# MKM14ZA5 register map
Vendor: Freescale Semiconductor, Inc.; Series: Kinetis_M; File version: 1.6
CPU: CM0PLUS r0p0, little endian, no MPU, no FPU, VTOR, 2 interrupt priority bits
Registers are 8-bit, read-write, reset 0x0 unless marked. A register's access mark holds for its fields unless they carry their own. Offsets are from the block's base; [hi:lo] are bit positions; {n}, {i} and the like mark numbered series.

## CMP0 — High-Speed Comparator (CMP), Voltage Reference (VREF) Digital-to-Analog Converter (DAC), and Analog Mux (ANMUX)
Base 0x40072000; register names take the prefix CMP0_
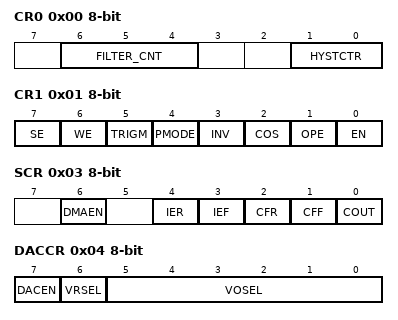
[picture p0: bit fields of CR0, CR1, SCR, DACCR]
0x00 CR0 — CMP Control Register 0
  [6:4] FILTER_CNT — Filter Sample Count
    0=Filter is disabled. If SE = 1, then COUT is a logic 0. This is not a legal state, and is not recommended. If SE = 0, COUT = COUTA.; 1=One sample must agree. The comparator output is simply sampled.; {v}={v} consecutive samples must agree (v=2..7)
  [1:0] HYSTCTR — Comparator hard block hysteresis control
    {v}=Level {v} (v=0..3)
0x01 CR1 — CMP Control Register 1
  [7] SE — Sample Enable
    0=Sampling mode is not selected; 1=Sampling mode is selected
  [6] WE — Windowing Enable
    0=Windowing mode is not selected; 1=Windowing mode is selected
  [5] TRIGM — Trigger Mode Enable
    0=Trigger mode is disabled; 1=Trigger mode is enabled
  [4] PMODE — Power Mode Select
    0=Low-Speed (LS) Comparison mode selected. In this mode, CMP has slower output propagation delay and lower current consumption.; 1=High-Speed (HS) Comparison mode selected. In this mode, CMP has faster output propagation delay and higher current consumption.
  [3] INV — Comparator INVERT
    0=Does not invert the comparator output; 1=Inverts the comparator output
  [2] COS — Comparator Output Select
    0=Set the filtered comparator output (CMPO) to equal COUT; 1=Set the unfiltered comparator output (CMPO) to equal COUTA
  [1] OPE — Comparator Output Pin Enable
    0=CMPO is not available on the associated CMPO output pin; 1=CMPO is available on the associated CMPO output pin
  [0] EN — Comparator Module Enable
    0=Analog Comparator is disabled; 1=Analog Comparator is enabled
0x02 FPR — CMP Filter Period Register
  [7:0] FILT_PER — Filter Sample Period
0x03 SCR — CMP Status and Control Register
  [6] DMAEN — DMA Enable Control
    0=DMA is disabled; 1=DMA is enabled
  [4] IER — Comparator Interrupt Enable Rising
    0=Interrupt is disabled; 1=Interrupt is enabled
  [3] IEF — Comparator Interrupt Enable Falling
    0=Interrupt is disabled; 1=Interrupt is enabled
  [2] CFR — Analog Comparator Flag Rising
    0=Rising-edge on COUT has not been detected; 1=Rising-edge on COUT has occurred
  [1] CFF — Analog Comparator Flag Falling
    0=Falling-edge on COUT has not been detected; 1=Falling-edge on COUT has occurred
  [0] COUT ro — Analog Comparator Output
0x04 DACCR — DAC Control Register
  [7] DACEN — DAC Enable
    0=DAC is disabled; 1=DAC is enabled
  [6] VRSEL — Supply Voltage Reference Source Select
    0=Vin1 is selected as resistor ladder network supply reference; 1=Vin2 is selected as resistor ladder network supply reference
  [5:0] VOSEL — DAC Output Voltage Select
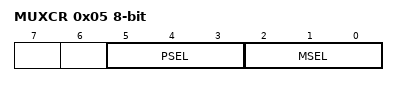
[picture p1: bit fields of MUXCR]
0x05 MUXCR — MUX Control Register
  [5:3] PSEL — Plus Input Mux Control
    {v}=IN{v} (v=0..7)
  [2:0] MSEL — Minus Input Mux Control
    {v}=IN{v} (v=0..7)

## CMP1 — High-Speed Comparator (CMP), Voltage Reference (VREF) Digital-to-Analog Converter (DAC), and Analog Mux (ANMUX)
Base 0x40072008; register names take the prefix CMP1_
Registers as CMP0.

## RCM — Reset Control Module
Base 0x4007B000; register names take the prefix RCM_
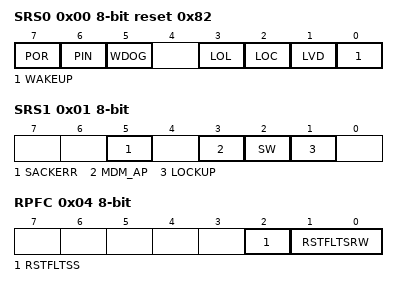
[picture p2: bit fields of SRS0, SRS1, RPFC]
0x00 SRS0 ro reset 0x82 — System Reset Status Register 0
  [7] POR — Power-On Reset
    0=Reset not caused by POR; 1=Reset caused by POR
  [6] PIN — External Reset Pin
    0=Reset not caused by external reset pin; 1=Reset caused by external reset pin
  [5] WDOG — Watchdog
    0=Reset not caused by watchdog timeout; 1=Reset caused by watchdog timeout
  [3] LOL — Loss-of-Lock Reset
    0=Reset not caused by a loss of lock in the PLL; 1=Reset caused by a loss of lock in the PLL
  [2] LOC — Loss-of-Clock Reset
    0=Reset not caused by a loss of external clock; 1=Reset caused by a loss of external clock
  [1] LVD — Low-Voltage Detect Reset
    0=Reset not caused by LVD trip or POR; 1=Reset caused by LVD trip or POR
  [0] WAKEUP — Low Leakage Wakeup Reset
    0=Reset not caused by wakeup source; 1=Reset caused by wakeup source
0x01 SRS1 ro — System Reset Status Register 1
  [5] SACKERR — Stop Mode Acknowledge Error Reset
    0=Reset not caused by peripheral failure to acknowledge attempt to enter stop mode; 1=Reset caused by peripheral failure to acknowledge attempt to enter stop mode
  [3] MDM_AP — MDM-AP System Reset Request
    0=Reset not caused by host debugger system setting of the System Reset Request bit; 1=Reset caused by host debugger system setting of the System Reset Request bit
  [2] SW — Software
    0=Reset not caused by software setting of SYSRESETREQ bit; 1=Reset caused by software setting of SYSRESETREQ bit
  [1] LOCKUP — Core Lockup
    0=Reset not caused by core LOCKUP event; 1=Reset caused by core LOCKUP event
0x04 RPFC — Reset Pin Filter Control register
  [2] RSTFLTSS — Reset Pin Filter Select in Stop Mode
    0=All filtering disabled; 1=LPO clock filter enabled
  [1:0] RSTFLTSRW — Reset Pin Filter Select in Run and Wait Modes
    0=All filtering disabled; 1=Bus clock filter enabled for normal operation; 2=LPO clock filter enabled for normal operation
0x05 RPFW — Reset Pin Filter Width register
  [4:0] RSTFLTSEL — Reset Pin Filter Bus Clock Select
    {v}=Bus clock filter count is {v+1} (v=0..31)
